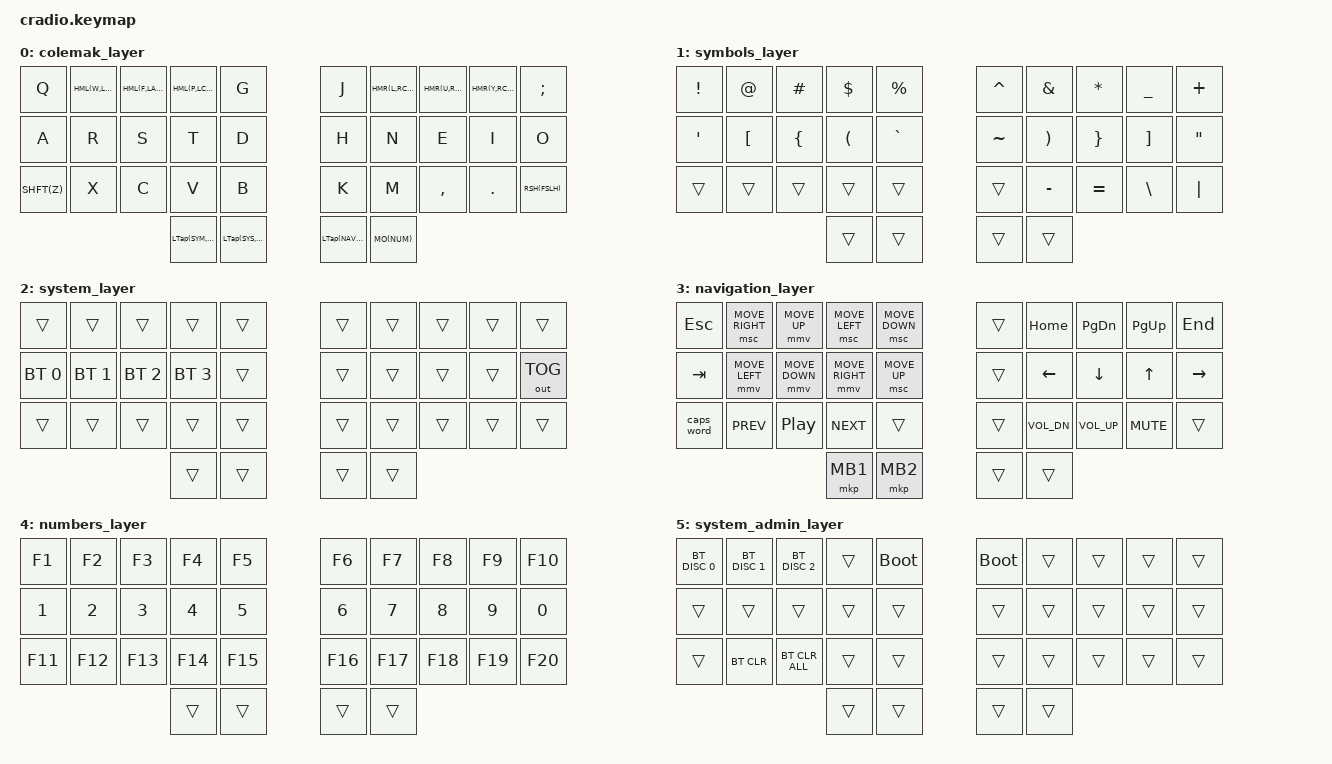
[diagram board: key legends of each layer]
// Copyright (c) 2022 The ZMK Contributors
// SPDX-License-Identifier: MIT
//
// vim: set ft=dts:

#include <behaviors.dtsi>
#include <dt-bindings/zmk/bt.h>
#include <dt-bindings/zmk/keys.h>
#include <dt-bindings/zmk/outputs.h>
#include <dt-bindings/zmk/pointing.h>

// define layers
#define COLEMAK 0
#define SYM 1
#define SYS 2
#define NAV 3
#define NUM 4
#define SYS_ADMIN 5

// Helper macros for cleaner keymap definitions
#define ___ &trans
#define XXX &none

// Home row mods macros
#define HML(key, mod) &ht mod key
#define HMR(key, mod) &ht mod key

// Layer tap macro (named LTap to avoid conflict with ZMK's LT key)
#define LTap(layer, key) &lt layer key

// Momentary layer macro
#define MO(layer) &mo layer

// Shift hold-tap macros (RSH to avoid conflict with ZMK's RSHFT key)
#define SHFT(key) &ht LSHFT key
#define RSH(key) &ht RSHFT key

// Mouse movement macros
#define MV_U &mmv MOVE_UP
#define MV_D &mmv MOVE_DOWN
#define MV_L &mmv MOVE_LEFT
#define MV_R &mmv MOVE_RIGHT

// Mouse scroll macros
#define SC_U &msc MOVE_UP
#define SC_D &msc MOVE_DOWN
#define SC_L &msc MOVE_LEFT
#define SC_R &msc MOVE_RIGHT

// Mouse button macros
#define MCLICK1 &mkp MB1
#define MCLICK2 &mkp MB2

// Media control macros
#define PREV &kp C_PREV
#define PLAY &kp C_PP
#define NEXT &kp C_NEXT
#define VOLD &kp C_VOL_DN
#define VOLU &kp C_VOL_UP
#define MUTE &kp C_MUTE

// Bluetooth macros
#define BT0 &bt BT_SEL 0
#define BT1 &bt BT_SEL 1
#define BT2 &bt BT_SEL 2
#define BT3 &bt BT_SEL 3
#define BT_DISC0 &bt BT_DISC 0
#define BT_DISC1 &bt BT_DISC 1
#define BT_DISC2 &bt BT_DISC 2
#define BTCLR &bt BT_CLR
#define BTCLRA &bt BT_CLR_ALL

// System macros
#define BOOT &bootloader
#define OUTTOG &out OUT_TOG

// Configure the layer tap.
&lt {
    // Setting quick-tap-ms will allow me to tap then hold the backspace key
    // and have it repeat.
    quick-tap-ms = <200>;
};

/ {
    behaviors {
        ht: hold_tap {
            compatible = "zmk,behavior-hold-tap";
            #binding-cells = <2>;
            flavor = "tap-preferred";
            tapping-term-ms = <200>;
            quick-tap-ms = <200>;
            #require-prior-idle-ms = <125>;
            bindings = <&kp>, <&kp>;
        };
    };

    conditional_layers {
        compatible = "zmk,conditional-layers";

        sys_admin_left {
            if-layers = <SYM SYS>;
            then-layer = <SYS_ADMIN>;
        };

        sys_admin_right {
            if-layers = <NAV NUM>;
            then-layer = <SYS_ADMIN>;
        };
    };

    keymap {
        compatible = "zmk,keymap";

        colemak_layer {
            bindings = <
        //╭────────────────┬────────────────┬────────────────┬────────────────┬────────────────╮   ╭────────────────┬────────────────┬────────────────┬────────────────┬────────────────╮
        //│       Q        │    W [CTRL]    │    F [ALT]     │    P [CMD]     │       G        │   │       J        │    L [CMD]     │    U [ALT]     │    Y [CTRL]    │       ;        │
            &kp Q            HML(W,LCTRL)     HML(F,LALT)      HML(P,LCMD)      &kp G                 &kp J            HMR(L,RCMD)      HMR(U,RALT)      HMR(Y,RCTRL)     &kp SEMI
        //├────────────────┼────────────────┼────────────────┼────────────────┼────────────────┤   ├────────────────┼────────────────┼────────────────┼────────────────┼────────────────┤
        //│       A        │       R        │       S        │       T        │       D        │   │       H        │       N        │       E        │       I        │       O        │
            &kp A            &kp R            &kp S            &kp T            &kp D                 &kp H            &kp N            &kp E            &kp I            &kp O
        //├────────────────┼────────────────┼────────────────┼────────────────┼────────────────┤   ├────────────────┼────────────────┼────────────────┼────────────────┼────────────────┤
        //│   Z [SHIFT]    │       X        │       C        │       V        │       B        │   │       K        │       M        │      , <       │      . >       │  / ? [SHIFT]   │
            SHFT(Z)          &kp X            &kp C            &kp V            &kp B                 &kp K            &kp M            &kp COMMA        &kp DOT          RSH(FSLH)
        //╰────────────────┴────────────────┴────────────────┼────────────────┼────────────────┤   ├────────────────┼────────────────┼────────────────┴────────────────┴────────────────╯
        //                                                   │  🔣 SYM [BSPC] │ ⚙️ SYS [SPACE] │   │ 🧭 NAV [ENTER] │    🔢 NUM      │
                                                              LTap(SYM,BSPC)   LTap(SYS,SPACE)       LTap(NAV,ENTER)  MO(NUM)
        //                                                   ╰────────────────┴────────────────╯   ╰────────────────┴────────────────╯
            >;
        };

        symbols_layer {
            bindings = <
        //╭────────────────┬────────────────┬────────────────┬────────────────┬────────────────╮   ╭────────────────┬────────────────┬────────────────┬────────────────┬────────────────╮
        //│       !        │       @        │       #        │       $        │       %        │   │       ^        │       &        │       *        │       _        │       +        │
            &kp EXCL         &kp AT           &kp HASH         &kp DLLR         &kp PRCNT            &kp CARET        &kp AMPS         &kp STAR         &kp UNDER        &kp PLUS
        //├────────────────┼────────────────┼────────────────┼────────────────┼────────────────┤   ├────────────────┼────────────────┼────────────────┼────────────────┼────────────────┤
        //│       '        │       [        │       {        │       (        │       `        │   │       ~        │       )        │       }        │       ]        │       "        │
            &kp APOS         &kp LBKT         &kp LBRC         &kp LPAR         &kp GRAVE            &kp TILDE        &kp RPAR         &kp RBRC         &kp RBKT         &kp DQT
        //├────────────────┼────────────────┼────────────────┼────────────────┼────────────────┤   ├────────────────┼────────────────┼────────────────┼────────────────┼────────────────┤
        //│                │                │                │                │                │   │                │       -        │       =        │       \        │       |        │
            ___              ___              ___              ___              ___                  ___              &kp MINUS        &kp EQUAL        &kp BSLH         &kp PIPE
        //╰────────────────┴────────────────┴────────────────┴────────────────┴────────────────┤   ├────────────────┴────────────────┴────────────────┴────────────────┴────────────────╯
        //                                                   │                │                │   │                │                │
                                                              ___              ___                   ___              ___
        //                                                   ╰────────────────┴────────────────╯   ╰────────────────┴────────────────╯
            >;
        };

        system_layer {
            bindings = <
        //╭────────────────┬────────────────┬────────────────┬────────────────┬────────────────╮   ╭────────────────┬────────────────┬────────────────┬────────────────┬────────────────╮
        //│                │                │                │                │                │   │                │                │                │                │                │
            ___              ___              ___              ___              ___                  ___              ___              ___              ___              ___
        //├────────────────┼────────────────┼────────────────┼────────────────┼────────────────┤   ├────────────────┼────────────────┼────────────────┼────────────────┼────────────────┤
        //│    🔵 BT 1     │    🔵 BT 2     │    🔵 BT 3     │    🔵 BT 4     │                │   │                │                │                │                │   🔀 OUT TOG   │
            BT0              BT1              BT2              BT3              ___                  ___              ___              ___              ___              OUTTOG
        //├────────────────┼────────────────┼────────────────┼────────────────┼────────────────┤   ├────────────────┼────────────────┼────────────────┼────────────────┼────────────────┤
        //│                │                │                │                │                │   │                │                │                │                │                │
            ___              ___              ___              ___              ___                  ___              ___              ___              ___              ___
        //╰────────────────┴────────────────┴────────────────┴────────────────┴────────────────┤   ├────────────────┴────────────────┴────────────────┴────────────────┴────────────────╯
        //                                                   │                │                │   │                │                │
                                                              ___              ___                   ___              ___
        //                                                   ╰────────────────┴────────────────╯   ╰────────────────┴────────────────╯
            >;
        };

        navigation_layer {
            bindings = <
        //╭────────────────┬────────────────┬────────────────┬────────────────┬────────────────╮   ╭────────────────┬────────────────┬────────────────┬────────────────┬────────────────╮
        //│      ESC       │    🔄 SC →     │    🖱️ MV ↑     │    🔄 SC ←     │    🔄 SC ↓     │   │                │      HOME      │    PG DOWN     │     PG UP      │      END       │
            &kp ESC          SC_R             MV_U             SC_L             SC_D                 ___              &kp HOME         &kp PG_DN        &kp PG_UP        &kp END
        //├────────────────┼────────────────┼────────────────┼────────────────┼────────────────┤   ├────────────────┼────────────────┼────────────────┼────────────────┼────────────────┤
        //│      TAB       │    🖱️ MV ←     │    🖱️ MV ↓     │    🖱️ MV →     │    🔄 SC ↑     │   │                │       👈       │       👇       │       👆       │       👉       │
            &kp TAB          MV_L             MV_D             MV_R             SC_U                 ___              &kp LEFT         &kp DOWN         &kp UP           &kp RIGHT
        //├────────────────┼────────────────┼────────────────┼────────────────┼────────────────┤   ├────────────────┼────────────────┼────────────────┼────────────────┼────────────────┤
        //│    🔡 CAPS     │    ⏮️ PREV     │    ⏯️ PLAY     │    ⏭️ NEXT     │                │   │                │    🔈 VOL-     │    🔊 VOL+     │    🔇 MUTE     │                │
           &caps_word        PREV             PLAY             NEXT             ___                  ___              VOLD             VOLU             MUTE             ___
        //╰────────────────┴────────────────┴────────────────┴────────────────┴────────────────┤   ╰────────────────┴────────────────┴────────────────┴────────────────┴────────────────╯
        //                                                   │     🖱️ L       │     🖱️ R       │   │                │                │
                                                              MCLICK1          MCLICK2               ___              ___
        //                                                   ╰────────────────┴────────────────╯   ╰────────────────┴────────────────╯
            >;
        };

        numbers_layer {
            bindings = <
        //╭────────────────┬────────────────┬────────────────┬────────────────┬────────────────╮   ╭────────────────┬────────────────┬────────────────┬────────────────┬────────────────╮
        //│       F1       │       F2       │       F3       │       F4       │       F5       │   │       F6       │       F7       │       F8       │       F9       │      F10       │
            &kp F1           &kp F2           &kp F3           &kp F4           &kp F5               &kp F6           &kp F7           &kp F8           &kp F9           &kp F10
        //├────────────────┼────────────────┼────────────────┼────────────────┼────────────────┤   ├────────────────┼────────────────┼────────────────┼────────────────┼────────────────┤
        //│       1        │       2        │       3        │       4        │       5        │   │       6        │       7        │       8        │       9        │       0        │
            &kp N1           &kp N2           &kp N3           &kp N4           &kp N5               &kp N6           &kp N7           &kp N8           &kp N9           &kp N0
        //├────────────────┼────────────────┼────────────────┼────────────────┼────────────────┤   ├────────────────┼────────────────┼────────────────┼────────────────┼────────────────┤
        //│      F11       │      F12       │      F13       │      F14       │      F15       │   │      F16       │      F17       │      F18       │      F19       │      F20       │
            &kp F11          &kp F12          &kp F13          &kp F14          &kp F15              &kp F16          &kp F17          &kp F18          &kp F19          &kp F20
        //╰────────────────┴────────────────┴────────────────┼────────────────┼────────────────┤   ├────────────────┼────────────────┼────────────────┴────────────────┴────────────────╯
        //                                                   │                │                │   │                │                │
                                                              ___              ___                   ___              ___
        //                                                  ╰────────────────┴────────────────╯    ╰────────────────┴────────────────╯
            >;
        };

        system_admin_layer {
            bindings = <
        //╭────────────────┬────────────────┬────────────────┬────────────────┬────────────────╮   ╭────────────────┬────────────────┬────────────────┬────────────────┬────────────────╮
        //│  ❌ BT DISC 1  │  ❌ BT DISC 2  │  ❌ BT DISC 3  │                │    🔄 BOOT     │   │    🔄 BOOT     │                │                │                │                │
            BT_DISC0         BT_DISC1         BT_DISC2         ___              BOOT                 BOOT             ___              ___              ___              ___
        //├────────────────┼────────────────┼────────────────┼────────────────┼────────────────┤   ├────────────────┼────────────────┼────────────────┼────────────────┼────────────────┤
        //│                │                │                │                │                │   │                │                │                │                │                │
            ___              ___              ___              ___              ___                  ___              ___              ___              ___              ___
        //├────────────────┼────────────────┼────────────────┼────────────────┼────────────────┤   ├────────────────┼────────────────┼────────────────┼────────────────┼────────────────┤
        //│                │   🗑️ BT CLR    │ 🗑️ BT CLR ALL  │                │                │   │                │                │                │                │                │
            ___              BTCLR            BTCLRA           ___              ___                  ___              ___              ___              ___              ___
        //╰────────────────┴────────────────┴────────────────┼────────────────┼────────────────┤   ├────────────────┼────────────────┼────────────────┴────────────────┴────────────────╯
        //                                                   │                │                │   │                │                │
                                                              ___              ___                   ___              ___
        //                                                   ╰────────────────┴────────────────╯   ╰────────────────┴────────────────╯
            >;
        };
    };
};
